AUTOSAR XML (schema 4-0-3)
package /CPLR_Code_pkg/CPLR_Code_swc
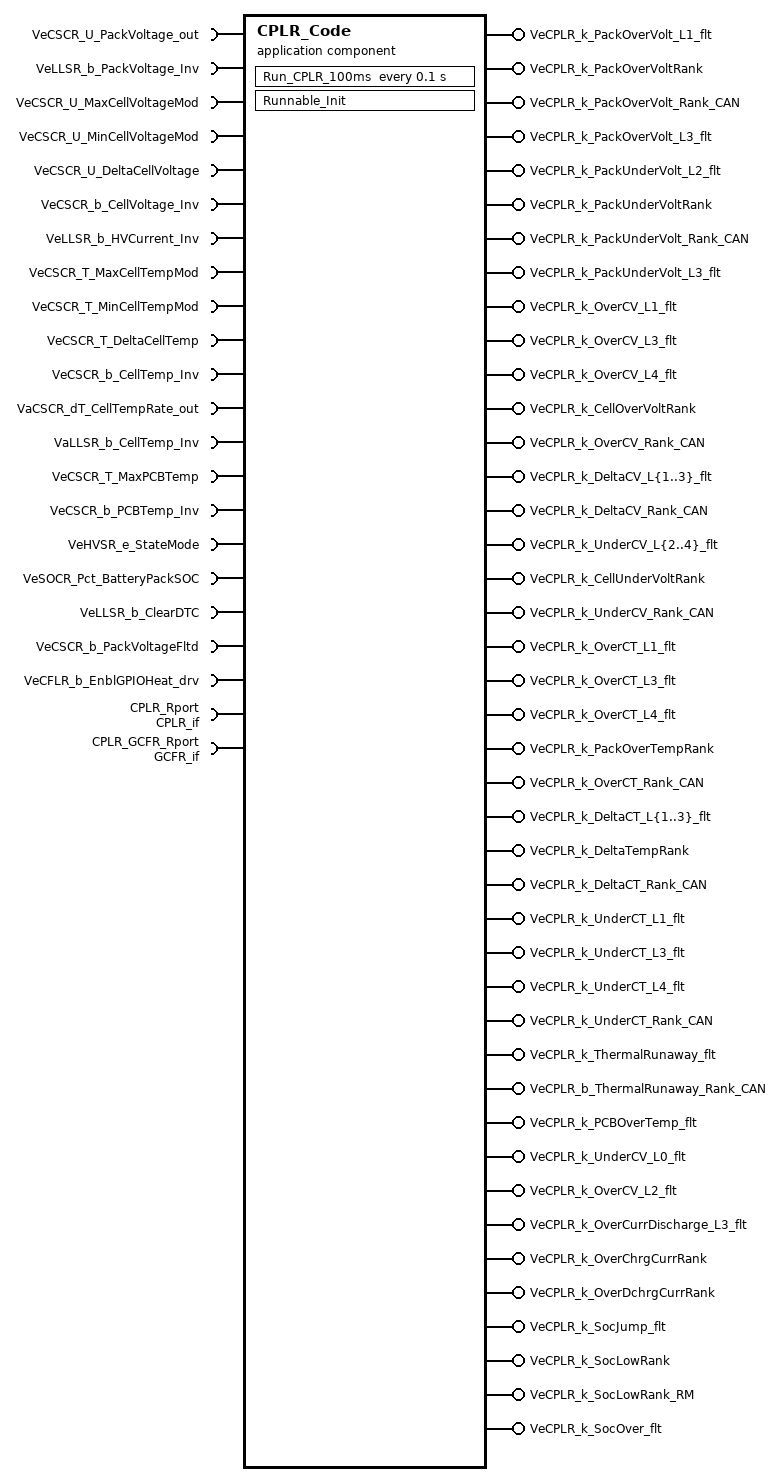
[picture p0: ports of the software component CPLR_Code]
  application sw component type CPLR_Code
    20 x require port:
      VeCSCR_U_PackVoltage_out: nonqueued-receiver-com-spec{data-element=VeCSCR_U_PackVoltage_out, init-value=0}, required-interface=VeCSCR_U_PackVoltage_out
      VeLLSR_b_PackVoltage_Inv: nonqueued-receiver-com-spec{data-element=VeLLSR_b_PackVoltage_Inv, init-value=0}, required-interface=VeLLSR_b_PackVoltage_Inv
      VeCSCR_U_MaxCellVoltageMod: nonqueued-receiver-com-spec{data-element=VeCSCR_U_MaxCellVoltageMod, init-value=0}, required-interface=VeCSCR_U_MaxCellVoltageMod
      VeCSCR_U_MinCellVoltageMod: nonqueued-receiver-com-spec{data-element=VeCSCR_U_MinCellVoltageMod, init-value=0}, required-interface=VeCSCR_U_MinCellVoltageMod
      VeCSCR_U_DeltaCellVoltage: nonqueued-receiver-com-spec{data-element=VeCSCR_U_DeltaCellVoltage, init-value=0}, required-interface=VeCSCR_U_DeltaCellVoltage
      VeCSCR_b_CellVoltage_Inv: nonqueued-receiver-com-spec{data-element=VeCSCR_b_CellVoltage_Inv, init-value=0}, required-interface=VeCSCR_b_CellVoltage_Inv
      VeLLSR_b_HVCurrent_Inv: nonqueued-receiver-com-spec{data-element=VeLLSR_b_HVCurrent_Inv, init-value=0}, required-interface=VeLLSR_b_HVCurrent_Inv
      VeCSCR_T_MaxCellTempMod: nonqueued-receiver-com-spec{data-element=VeCSCR_T_MaxCellTempMod, init-value=0}, required-interface=VeCSCR_T_MaxCellTempMod
      VeCSCR_T_MinCellTempMod: nonqueued-receiver-com-spec{data-element=VeCSCR_T_MinCellTempMod, init-value=0}, required-interface=VeCSCR_T_MinCellTempMod
      VeCSCR_T_DeltaCellTemp: nonqueued-receiver-com-spec{data-element=VeCSCR_T_DeltaCellTemp, init-value=0}, required-interface=VeCSCR_T_DeltaCellTemp
      VeCSCR_b_CellTemp_Inv: nonqueued-receiver-com-spec{data-element=VeCSCR_b_CellTemp_Inv, init-value=0}, required-interface=VeCSCR_b_CellTemp_Inv
      VaCSCR_dT_CellTempRate_out: nonqueued-receiver-com-spec{data-element=VaCSCR_dT_CellTempRate_out, init-value=16 x 0}, required-interface=VaCSCR_dT_CellTempRate_out
      VaLLSR_b_CellTemp_Inv: nonqueued-receiver-com-spec{data-element=VaLLSR_b_CellTemp_Inv, init-value=16 x 0}, required-interface=VaLLSR_b_CellTemp_Inv
      VeCSCR_T_MaxPCBTemp: nonqueued-receiver-com-spec{data-element=VeCSCR_T_MaxPCBTemp, init-value=0}, required-interface=VeCSCR_T_MaxPCBTemp
      VeCSCR_b_PCBTemp_Inv: nonqueued-receiver-com-spec{data-element=VeCSCR_b_PCBTemp_Inv, init-value=0}, required-interface=VeCSCR_b_PCBTemp_Inv
      VeHVSR_e_StateMode: nonqueued-receiver-com-spec{data-element=VeHVSR_e_StateMode, init-value=CeHVSR_e_StateModeReserved}, required-interface=VeHVSR_e_StateMode
      VeSOCR_Pct_BatteryPackSOC: nonqueued-receiver-com-spec{data-element=VeSOCR_Pct_BatteryPackSOC, init-value=0}, required-interface=VeSOCR_Pct_BatteryPackSOC
      VeLLSR_b_ClearDTC: nonqueued-receiver-com-spec{data-element=VeLLSR_b_ClearDTC, init-value=0}, required-interface=VeLLSR_b_ClearDTC
      VeCSCR_b_PackVoltageFltd: nonqueued-receiver-com-spec{data-element=VeCSCR_b_PackVoltageFltd, init-value=0}, required-interface=VeCSCR_b_PackVoltageFltd
      VeCFLR_b_EnblGPIOHeat_drv: nonqueued-receiver-com-spec{data-element=VeCFLR_b_EnblGPIOHeat_drv, init-value=0}, required-interface=VeCFLR_b_EnblGPIOHeat_drv
    48 x provide port:
      VeCPLR_k_PackOverVolt_L1_flt: nonqueued-sender-com-spec{data-element=VeCPLR_k_PackOverVolt_L1_flt, init-value=0}, provided-interface=VeCPLR_k_PackOverVolt_L1_flt
      VeCPLR_k_PackOverVoltRank: nonqueued-sender-com-spec{data-element=VeCPLR_k_PackOverVoltRank, init-value=0}, provided-interface=VeCPLR_k_PackOverVoltRank
      VeCPLR_k_PackOverVolt_Rank_CAN: nonqueued-sender-com-spec{data-element=VeCPLR_k_PackOverVolt_Rank_CAN, init-value=0}, provided-interface=VeCPLR_k_PackOverVolt_Rank_CAN
      VeCPLR_k_PackOverVolt_L3_flt: nonqueued-sender-com-spec{data-element=VeCPLR_k_PackOverVolt_L3_flt, init-value=0}, provided-interface=VeCPLR_k_PackOverVolt_L3_flt
      VeCPLR_k_PackUnderVolt_L2_flt: nonqueued-sender-com-spec{data-element=VeCPLR_k_PackUnderVolt_L2_flt, init-value=0}, provided-interface=VeCPLR_k_PackUnderVolt_L2_flt
      VeCPLR_k_PackUnderVoltRank: nonqueued-sender-com-spec{data-element=VeCPLR_k_PackUnderVoltRank, init-value=0}, provided-interface=VeCPLR_k_PackUnderVoltRank
      VeCPLR_k_PackUnderVolt_Rank_CAN: nonqueued-sender-com-spec{data-element=VeCPLR_k_PackUnderVolt_Rank_CAN, init-value=0}, provided-interface=VeCPLR_k_PackUnderVolt_Rank_CAN
      VeCPLR_k_PackUnderVolt_L3_flt: nonqueued-sender-com-spec{data-element=VeCPLR_k_PackUnderVolt_L3_flt, init-value=0}, provided-interface=VeCPLR_k_PackUnderVolt_L3_flt
      VeCPLR_k_OverCV_L1_flt: nonqueued-sender-com-spec{data-element=VeCPLR_k_OverCV_L1_flt, init-value=0}, provided-interface=VeCPLR_k_OverCV_L1_flt
      VeCPLR_k_OverCV_L3_flt: nonqueued-sender-com-spec{data-element=VeCPLR_k_OverCV_L3_flt, init-value=0}, provided-interface=VeCPLR_k_OverCV_L3_flt
      VeCPLR_k_OverCV_L4_flt: nonqueued-sender-com-spec{data-element=VeCPLR_k_OverCV_L4_flt, init-value=0}, provided-interface=VeCPLR_k_OverCV_L4_flt
      VeCPLR_k_CellOverVoltRank: nonqueued-sender-com-spec{data-element=VeCPLR_k_CellOverVoltRank, init-value=0}, provided-interface=VeCPLR_k_CellOverVoltRank
      VeCPLR_k_OverCV_Rank_CAN: nonqueued-sender-com-spec{data-element=VeCPLR_k_OverCV_Rank_CAN, init-value=0}, provided-interface=VeCPLR_k_OverCV_Rank_CAN
      VeCPLR_k_DeltaCV_L{1..3}_flt: nonqueued-sender-com-spec{data-element=VeCPLR_k_DeltaCV_L{1..3}_flt, init-value=0}, provided-interface=VeCPLR_k_DeltaCV_L{1..3}_flt
      VeCPLR_k_DeltaCV_Rank_CAN: nonqueued-sender-com-spec{data-element=VeCPLR_k_DeltaCV_Rank_CAN, init-value=0}, provided-interface=VeCPLR_k_DeltaCV_Rank_CAN
      VeCPLR_k_UnderCV_L{2..4}_flt: nonqueued-sender-com-spec{data-element=VeCPLR_k_UnderCV_L{2..4}_flt, init-value=0}, provided-interface=VeCPLR_k_UnderCV_L{2..4}_flt
      VeCPLR_k_CellUnderVoltRank: nonqueued-sender-com-spec{data-element=VeCPLR_k_CellUnderVoltRank, init-value=0}, provided-interface=VeCPLR_k_CellUnderVoltRank
      VeCPLR_k_UnderCV_Rank_CAN: nonqueued-sender-com-spec{data-element=VeCPLR_k_UnderCV_Rank_CAN, init-value=0}, provided-interface=VeCPLR_k_UnderCV_Rank_CAN
      VeCPLR_k_OverCT_L1_flt: nonqueued-sender-com-spec{data-element=VeCPLR_k_OverCT_L1_flt, init-value=0}, provided-interface=VeCPLR_k_OverCT_L1_flt
      VeCPLR_k_OverCT_L3_flt: nonqueued-sender-com-spec{data-element=VeCPLR_k_OverCT_L3_flt, init-value=0}, provided-interface=VeCPLR_k_OverCT_L3_flt
      VeCPLR_k_OverCT_L4_flt: nonqueued-sender-com-spec{data-element=VeCPLR_k_OverCT_L4_flt, init-value=0}, provided-interface=VeCPLR_k_OverCT_L4_flt
      VeCPLR_k_PackOverTempRank: nonqueued-sender-com-spec{data-element=VeCPLR_k_PackOverTempRank, init-value=0}, provided-interface=VeCPLR_k_PackOverTempRank
      VeCPLR_k_OverCT_Rank_CAN: nonqueued-sender-com-spec{data-element=VeCPLR_k_OverCT_Rank_CAN, init-value=0}, provided-interface=VeCPLR_k_OverCT_Rank_CAN
      VeCPLR_k_DeltaCT_L{1..3}_flt: nonqueued-sender-com-spec{data-element=VeCPLR_k_DeltaCT_L{1..3}_flt, init-value=0}, provided-interface=VeCPLR_k_DeltaCT_L{1..3}_flt
      VeCPLR_k_DeltaTempRank: nonqueued-sender-com-spec{data-element=VeCPLR_k_DeltaTempRank, init-value=0}, provided-interface=VeCPLR_k_DeltaTempRank
      VeCPLR_k_DeltaCT_Rank_CAN: nonqueued-sender-com-spec{data-element=VeCPLR_k_DeltaCT_Rank_CAN, init-value=0}, provided-interface=VeCPLR_k_DeltaCT_Rank_CAN
      VeCPLR_k_UnderCT_L1_flt: nonqueued-sender-com-spec{data-element=VeCPLR_k_UnderCT_L1_flt, init-value=0}, provided-interface=VeCPLR_k_UnderCT_L1_flt
      VeCPLR_k_UnderCT_L3_flt: nonqueued-sender-com-spec{data-element=VeCPLR_k_UnderCT_L3_flt, init-value=0}, provided-interface=VeCPLR_k_UnderCT_L3_flt
      VeCPLR_k_UnderCT_L4_flt: nonqueued-sender-com-spec{data-element=VeCPLR_k_UnderCT_L4_flt, init-value=0}, provided-interface=VeCPLR_k_UnderCT_L4_flt
      VeCPLR_k_UnderCT_Rank_CAN: nonqueued-sender-com-spec{data-element=VeCPLR_k_UnderCT_Rank_CAN, init-value=0}, provided-interface=VeCPLR_k_UnderCT_Rank_CAN
      VeCPLR_k_ThermalRunaway_flt: nonqueued-sender-com-spec{data-element=VeCPLR_k_ThermalRunaway_flt, init-value=0}, provided-interface=VeCPLR_k_ThermalRunaway_flt
      VeCPLR_b_ThermalRunaway_Rank_CAN: nonqueued-sender-com-spec{data-element=VeCPLR_b_ThermalRunaway_Rank_CAN, init-value=0}, provided-interface=VeCPLR_b_ThermalRunaway_Rank_CAN
      VeCPLR_k_PCBOverTemp_flt: nonqueued-sender-com-spec{data-element=VeCPLR_k_PCBOverTemp_flt, init-value=0}, provided-interface=VeCPLR_k_PCBOverTemp_flt
      VeCPLR_k_UnderCV_L0_flt: nonqueued-sender-com-spec{data-element=VeCPLR_k_UnderCV_L0_flt, init-value=0}, provided-interface=VeCPLR_k_UnderCV_L0_flt
      VeCPLR_k_OverCV_L2_flt: nonqueued-sender-com-spec{data-element=VeCPLR_k_OverCV_L2_flt, init-value=0}, provided-interface=VeCPLR_k_OverCV_L2_flt
      VeCPLR_k_OverCurrDischarge_L3_flt: nonqueued-sender-com-spec{data-element=VeCPLR_k_OverCurrDischarge_L3_flt, init-value=0}, provided-interface=VeCPLR_k_OverCurrDischarge_L3_flt
      VeCPLR_k_OverChrgCurrRank: nonqueued-sender-com-spec{data-element=VeCPLR_k_OverChrgCurrRank, init-value=0}, provided-interface=VeCPLR_k_OverChrgCurrRank
      VeCPLR_k_OverDchrgCurrRank: nonqueued-sender-com-spec{data-element=VeCPLR_k_OverDchrgCurrRank, init-value=0}, provided-interface=VeCPLR_k_OverDchrgCurrRank
      VeCPLR_k_SocJump_flt: nonqueued-sender-com-spec{data-element=VeCPLR_k_SocJump_flt, init-value=0}, provided-interface=VeCPLR_k_SocJump_flt
      VeCPLR_k_SocLowRank: nonqueued-sender-com-spec{data-element=VeCPLR_k_SocLowRank, init-value=0}, provided-interface=VeCPLR_k_SocLowRank
      VeCPLR_k_SocLowRank_RM: nonqueued-sender-com-spec{data-element=VeCPLR_k_SocLowRank_RM, init-value=0}, provided-interface=VeCPLR_k_SocLowRank_RM
      VeCPLR_k_SocOver_flt: nonqueued-sender-com-spec{data-element=VeCPLR_k_SocOver_flt, init-value=0}, provided-interface=VeCPLR_k_SocOver_flt
    require port CPLR_Rport: required-interface=CPLR_if
    require port CPLR_GCFR_Rport: required-interface=GCFR_if
    behavior CPLR_Code: data-type-mapping=[CPLR_CodeDataTypeMappingsSet, WorkingDataTypeMappingsSet], handle-termination-and-restart=NO-SUPPORT
      timing event Event_Run_CPLR_100ms: start-on-event=Run_CPLR_100ms, period=0.1
      runnable Runnable_Init: symbol=CPLR_Code_Init
        data-send-points:
          32 x access:
            OUT_VeCPLR_k_UnderCV_L0_flt_VeCPLR_k_UnderCV_L0_flt: accessed-variable=VeCPLR_k_UnderCV_L0_flt.VeCPLR_k_UnderCV_L0_flt
            OUT_VeCPLR_k_OverCV_L2_flt_VeCPLR_k_OverCV_L2_flt: accessed-variable=VeCPLR_k_OverCV_L2_flt.VeCPLR_k_OverCV_L2_flt
            OUT_VeCPLR_k_OverCurrDischarge_L3_flt_VeCPLR_f7761c5b48d64ec0: accessed-variable=VeCPLR_k_OverCurrDischarge_L3_flt.VeCPLR_k_OverCurrDischarge_L3_flt
            OUT_VeCPLR_k_OverChrgCurrRank_VeCPLR_k_OverChrgCurrRank: accessed-variable=VeCPLR_k_OverChrgCurrRank.VeCPLR_k_OverChrgCurrRank
            OUT_VeCPLR_k_OverDchrgCurrRank_VeCPLR_k_OverDchrgCurrRank: accessed-variable=VeCPLR_k_OverDchrgCurrRank.VeCPLR_k_OverDchrgCurrRank
            OUT_VeCPLR_k_SocJump_flt_VeCPLR_k_SocJump_flt: accessed-variable=VeCPLR_k_SocJump_flt.VeCPLR_k_SocJump_flt
            OUT_VeCPLR_k_SocLowRank_VeCPLR_k_SocLowRank: accessed-variable=VeCPLR_k_SocLowRank.VeCPLR_k_SocLowRank
            OUT_VeCPLR_k_SocLowRank_RM_VeCPLR_k_SocLowRank_RM: accessed-variable=VeCPLR_k_SocLowRank_RM.VeCPLR_k_SocLowRank_RM
            OUT_VeCPLR_k_SocOver_flt_VeCPLR_k_SocOver_flt: accessed-variable=VeCPLR_k_SocOver_flt.VeCPLR_k_SocOver_flt
            OUT_VeCPLR_k_PackOverVolt_L1_flt_VeCPLR_k_PackOverVolt_L1_flt: accessed-variable=VeCPLR_k_PackOverVolt_L1_flt.VeCPLR_k_PackOverVolt_L1_flt
            OUT_VeCPLR_k_PackOverVolt_L3_flt_VeCPLR_k_PackOverVolt_L3_flt: accessed-variable=VeCPLR_k_PackOverVolt_L3_flt.VeCPLR_k_PackOverVolt_L3_flt
            OUT_VeCPLR_k_PackUnderVolt_L2_flt_VeCPLR_k_Pa_e03c45c6c9c0b4ad: accessed-variable=VeCPLR_k_PackUnderVolt_L2_flt.VeCPLR_k_PackUnderVolt_L2_flt
            OUT_VeCPLR_k_PackUnderVolt_L3_flt_VeCPLR_k_Pa_cc559624e727b183: accessed-variable=VeCPLR_k_PackUnderVolt_L3_flt.VeCPLR_k_PackUnderVolt_L3_flt
            OUT_VeCPLR_k_OverCV_L1_flt_VeCPLR_k_OverCV_L1_flt: accessed-variable=VeCPLR_k_OverCV_L1_flt.VeCPLR_k_OverCV_L1_flt
            OUT_VeCPLR_k_OverCV_L3_flt_VeCPLR_k_OverCV_L3_flt: accessed-variable=VeCPLR_k_OverCV_L3_flt.VeCPLR_k_OverCV_L3_flt
            OUT_VeCPLR_k_OverCV_L4_flt_VeCPLR_k_OverCV_L4_flt: accessed-variable=VeCPLR_k_OverCV_L4_flt.VeCPLR_k_OverCV_L4_flt
            OUT_VeCPLR_k_DeltaCV_L{1..3}_flt_VeCPLR_k_DeltaCV_L{1..3}_flt: accessed-variable=VeCPLR_k_DeltaCV_L{1..3}_flt.VeCPLR_k_DeltaCV_L{1..3}_flt
            OUT_VeCPLR_k_UnderCV_L{2..4}_flt_VeCPLR_k_UnderCV_L{2..4}_flt: accessed-variable=VeCPLR_k_UnderCV_L{2..4}_flt.VeCPLR_k_UnderCV_L{2..4}_flt
            OUT_VeCPLR_k_OverCT_L1_flt_VeCPLR_k_OverCT_L1_flt: accessed-variable=VeCPLR_k_OverCT_L1_flt.VeCPLR_k_OverCT_L1_flt
            OUT_VeCPLR_k_OverCT_L3_flt_VeCPLR_k_OverCT_L3_flt: accessed-variable=VeCPLR_k_OverCT_L3_flt.VeCPLR_k_OverCT_L3_flt
            OUT_VeCPLR_k_OverCT_L4_flt_VeCPLR_k_OverCT_L4_flt: accessed-variable=VeCPLR_k_OverCT_L4_flt.VeCPLR_k_OverCT_L4_flt
            OUT_VeCPLR_k_DeltaCT_L{1..3}_flt_VeCPLR_k_DeltaCT_L{1..3}_flt: accessed-variable=VeCPLR_k_DeltaCT_L{1..3}_flt.VeCPLR_k_DeltaCT_L{1..3}_flt
            OUT_VeCPLR_k_UnderCT_L1_flt_VeCPLR_k_UnderCT_L1_flt: accessed-variable=VeCPLR_k_UnderCT_L1_flt.VeCPLR_k_UnderCT_L1_flt
            OUT_VeCPLR_k_UnderCT_L3_flt_VeCPLR_k_UnderCT_L3_flt: accessed-variable=VeCPLR_k_UnderCT_L3_flt.VeCPLR_k_UnderCT_L3_flt
            OUT_VeCPLR_k_UnderCT_L4_flt_VeCPLR_k_UnderCT_L4_flt: accessed-variable=VeCPLR_k_UnderCT_L4_flt.VeCPLR_k_UnderCT_L4_flt
            OUT_VeCPLR_k_ThermalRunaway_flt_VeCPLR_k_ThermalRunaway_flt: accessed-variable=VeCPLR_k_ThermalRunaway_flt.VeCPLR_k_ThermalRunaway_flt
      runnable Run_CPLR_100ms
        data-read-access:
          20 x access:
            IN_VaCSCR_dT_CellTempRate_out_VaCSCR_dT_CellTempRate_out: accessed-variable=VaCSCR_dT_CellTempRate_out.VaCSCR_dT_CellTempRate_out
            IN_VaLLSR_b_CellTemp_Inv_VaLLSR_b_CellTemp_Inv: accessed-variable=VaLLSR_b_CellTemp_Inv.VaLLSR_b_CellTemp_Inv
            IN_VeCFLR_b_EnblGPIOHeat_drv_VeCFLR_b_EnblGPIOHeat_drv: accessed-variable=VeCFLR_b_EnblGPIOHeat_drv.VeCFLR_b_EnblGPIOHeat_drv
            IN_VeCSCR_T_DeltaCellTemp_VeCSCR_T_DeltaCellTemp: accessed-variable=VeCSCR_T_DeltaCellTemp.VeCSCR_T_DeltaCellTemp
            IN_VeCSCR_T_MaxCellTempMod_VeCSCR_T_MaxCellTempMod: accessed-variable=VeCSCR_T_MaxCellTempMod.VeCSCR_T_MaxCellTempMod
            IN_VeCSCR_T_MaxPCBTemp_VeCSCR_T_MaxPCBTemp: accessed-variable=VeCSCR_T_MaxPCBTemp.VeCSCR_T_MaxPCBTemp
            IN_VeCSCR_T_MinCellTempMod_VeCSCR_T_MinCellTempMod: accessed-variable=VeCSCR_T_MinCellTempMod.VeCSCR_T_MinCellTempMod
            IN_VeCSCR_U_DeltaCellVoltage_VeCSCR_U_DeltaCellVoltage: accessed-variable=VeCSCR_U_DeltaCellVoltage.VeCSCR_U_DeltaCellVoltage
            IN_VeCSCR_U_MaxCellVoltageMod_VeCSCR_U_MaxCellVoltageMod: accessed-variable=VeCSCR_U_MaxCellVoltageMod.VeCSCR_U_MaxCellVoltageMod
            IN_VeCSCR_U_MinCellVoltageMod_VeCSCR_U_MinCellVoltageMod: accessed-variable=VeCSCR_U_MinCellVoltageMod.VeCSCR_U_MinCellVoltageMod
            IN_VeCSCR_U_PackVoltage_out_VeCSCR_U_PackVoltage_out: accessed-variable=VeCSCR_U_PackVoltage_out.VeCSCR_U_PackVoltage_out
            IN_VeCSCR_b_CellTemp_Inv_VeCSCR_b_CellTemp_Inv: accessed-variable=VeCSCR_b_CellTemp_Inv.VeCSCR_b_CellTemp_Inv
            IN_VeCSCR_b_CellVoltage_Inv_VeCSCR_b_CellVoltage_Inv: accessed-variable=VeCSCR_b_CellVoltage_Inv.VeCSCR_b_CellVoltage_Inv
            IN_VeCSCR_b_PCBTemp_Inv_VeCSCR_b_PCBTemp_Inv: accessed-variable=VeCSCR_b_PCBTemp_Inv.VeCSCR_b_PCBTemp_Inv
            IN_VeCSCR_b_PackVoltageFltd_VeCSCR_b_PackVoltageFltd: accessed-variable=VeCSCR_b_PackVoltageFltd.VeCSCR_b_PackVoltageFltd
            IN_VeHVSR_e_StateMode_VeHVSR_e_StateMode: accessed-variable=VeHVSR_e_StateMode.VeHVSR_e_StateMode
            IN_VeLLSR_b_ClearDTC_VeLLSR_b_ClearDTC: accessed-variable=VeLLSR_b_ClearDTC.VeLLSR_b_ClearDTC
            IN_VeLLSR_b_HVCurrent_Inv_VeLLSR_b_HVCurrent_Inv: accessed-variable=VeLLSR_b_HVCurrent_Inv.VeLLSR_b_HVCurrent_Inv
            IN_VeLLSR_b_PackVoltage_Inv_VeLLSR_b_PackVoltage_Inv: accessed-variable=VeLLSR_b_PackVoltage_Inv.VeLLSR_b_PackVoltage_Inv
            IN_VeSOCR_Pct_BatteryPackSOC_VeSOCR_Pct_BatteryPackSOC: accessed-variable=VeSOCR_Pct_BatteryPackSOC.VeSOCR_Pct_BatteryPackSOC
        data-send-points:
          48 x access:
            OUT_VeCPLR_k_PackOverVolt_L1_flt_VeCPLR_k_PackOverVolt_L1_flt: accessed-variable=VeCPLR_k_PackOverVolt_L1_flt.VeCPLR_k_PackOverVolt_L1_flt
            OUT_VeCPLR_k_PackOverVoltRank_VeCPLR_k_PackOverVoltRank: accessed-variable=VeCPLR_k_PackOverVoltRank.VeCPLR_k_PackOverVoltRank
            OUT_VeCPLR_k_PackOverVolt_Rank_CAN_VeCPLR_k_P_b2e92d86be282e41: accessed-variable=VeCPLR_k_PackOverVolt_Rank_CAN.VeCPLR_k_PackOverVolt_Rank_CAN
            OUT_VeCPLR_k_PackOverVolt_L3_flt_VeCPLR_k_PackOverVolt_L3_flt: accessed-variable=VeCPLR_k_PackOverVolt_L3_flt.VeCPLR_k_PackOverVolt_L3_flt
            OUT_VeCPLR_k_PackUnderVolt_L2_flt_VeCPLR_k_Pa_e03c45c6c9c0b4ad: accessed-variable=VeCPLR_k_PackUnderVolt_L2_flt.VeCPLR_k_PackUnderVolt_L2_flt
            OUT_VeCPLR_k_PackUnderVoltRank_VeCPLR_k_PackUnderVoltRank: accessed-variable=VeCPLR_k_PackUnderVoltRank.VeCPLR_k_PackUnderVoltRank
            OUT_VeCPLR_k_PackUnderVolt_Rank_CAN_VeCPLR_k_ec56d7bc020496a0: accessed-variable=VeCPLR_k_PackUnderVolt_Rank_CAN.VeCPLR_k_PackUnderVolt_Rank_CAN
            OUT_VeCPLR_k_PackUnderVolt_L3_flt_VeCPLR_k_Pa_cc559624e727b183: accessed-variable=VeCPLR_k_PackUnderVolt_L3_flt.VeCPLR_k_PackUnderVolt_L3_flt
            OUT_VeCPLR_k_OverCV_L1_flt_VeCPLR_k_OverCV_L1_flt: accessed-variable=VeCPLR_k_OverCV_L1_flt.VeCPLR_k_OverCV_L1_flt
            OUT_VeCPLR_k_OverCV_L3_flt_VeCPLR_k_OverCV_L3_flt: accessed-variable=VeCPLR_k_OverCV_L3_flt.VeCPLR_k_OverCV_L3_flt
            OUT_VeCPLR_k_OverCV_L4_flt_VeCPLR_k_OverCV_L4_flt: accessed-variable=VeCPLR_k_OverCV_L4_flt.VeCPLR_k_OverCV_L4_flt
            OUT_VeCPLR_k_CellOverVoltRank_VeCPLR_k_CellOverVoltRank: accessed-variable=VeCPLR_k_CellOverVoltRank.VeCPLR_k_CellOverVoltRank
            OUT_VeCPLR_k_OverCV_Rank_CAN_VeCPLR_k_OverCV_Rank_CAN: accessed-variable=VeCPLR_k_OverCV_Rank_CAN.VeCPLR_k_OverCV_Rank_CAN
            OUT_VeCPLR_k_DeltaCV_L{1..3}_flt_VeCPLR_k_DeltaCV_L{1..3}_flt: accessed-variable=VeCPLR_k_DeltaCV_L{1..3}_flt.VeCPLR_k_DeltaCV_L{1..3}_flt
            OUT_VeCPLR_k_DeltaCV_Rank_CAN_VeCPLR_k_DeltaCV_Rank_CAN: accessed-variable=VeCPLR_k_DeltaCV_Rank_CAN.VeCPLR_k_DeltaCV_Rank_CAN
            OUT_VeCPLR_k_UnderCV_L{2..4}_flt_VeCPLR_k_UnderCV_L{2..4}_flt: accessed-variable=VeCPLR_k_UnderCV_L{2..4}_flt.VeCPLR_k_UnderCV_L{2..4}_flt
            OUT_VeCPLR_k_CellUnderVoltRank_VeCPLR_k_CellUnderVoltRank: accessed-variable=VeCPLR_k_CellUnderVoltRank.VeCPLR_k_CellUnderVoltRank
            OUT_VeCPLR_k_UnderCV_Rank_CAN_VeCPLR_k_UnderCV_Rank_CAN: accessed-variable=VeCPLR_k_UnderCV_Rank_CAN.VeCPLR_k_UnderCV_Rank_CAN
            OUT_VeCPLR_k_OverCT_L1_flt_VeCPLR_k_OverCT_L1_flt: accessed-variable=VeCPLR_k_OverCT_L1_flt.VeCPLR_k_OverCT_L1_flt
            OUT_VeCPLR_k_OverCT_L3_flt_VeCPLR_k_OverCT_L3_flt: accessed-variable=VeCPLR_k_OverCT_L3_flt.VeCPLR_k_OverCT_L3_flt
            OUT_VeCPLR_k_OverCT_L4_flt_VeCPLR_k_OverCT_L4_flt: accessed-variable=VeCPLR_k_OverCT_L4_flt.VeCPLR_k_OverCT_L4_flt
            OUT_VeCPLR_k_PackOverTempRank_VeCPLR_k_PackOverTempRank: accessed-variable=VeCPLR_k_PackOverTempRank.VeCPLR_k_PackOverTempRank
            OUT_VeCPLR_k_OverCT_Rank_CAN_VeCPLR_k_OverCT_Rank_CAN: accessed-variable=VeCPLR_k_OverCT_Rank_CAN.VeCPLR_k_OverCT_Rank_CAN
            OUT_VeCPLR_k_DeltaCT_L{1..3}_flt_VeCPLR_k_DeltaCT_L{1..3}_flt: accessed-variable=VeCPLR_k_DeltaCT_L{1..3}_flt.VeCPLR_k_DeltaCT_L{1..3}_flt
            OUT_VeCPLR_k_DeltaTempRank_VeCPLR_k_DeltaTempRank: accessed-variable=VeCPLR_k_DeltaTempRank.VeCPLR_k_DeltaTempRank
            OUT_VeCPLR_k_DeltaCT_Rank_CAN_VeCPLR_k_DeltaCT_Rank_CAN: accessed-variable=VeCPLR_k_DeltaCT_Rank_CAN.VeCPLR_k_DeltaCT_Rank_CAN
            OUT_VeCPLR_k_UnderCT_L1_flt_VeCPLR_k_UnderCT_L1_flt: accessed-variable=VeCPLR_k_UnderCT_L1_flt.VeCPLR_k_UnderCT_L1_flt
            OUT_VeCPLR_k_UnderCT_L3_flt_VeCPLR_k_UnderCT_L3_flt: accessed-variable=VeCPLR_k_UnderCT_L3_flt.VeCPLR_k_UnderCT_L3_flt
            OUT_VeCPLR_k_UnderCT_L4_flt_VeCPLR_k_UnderCT_L4_flt: accessed-variable=VeCPLR_k_UnderCT_L4_flt.VeCPLR_k_UnderCT_L4_flt
            OUT_VeCPLR_k_UnderCT_Rank_CAN_VeCPLR_k_UnderCT_Rank_CAN: accessed-variable=VeCPLR_k_UnderCT_Rank_CAN.VeCPLR_k_UnderCT_Rank_CAN
            OUT_VeCPLR_k_ThermalRunaway_flt_VeCPLR_k_ThermalRunaway_flt: accessed-variable=VeCPLR_k_ThermalRunaway_flt.VeCPLR_k_ThermalRunaway_flt
            OUT_VeCPLR_b_ThermalRunaway_Rank_CAN_VeCPLR_b_dc09d45ce0f05caf: accessed-variable=VeCPLR_b_ThermalRunaway_Rank_CAN.VeCPLR_b_ThermalRunaway_Rank_CAN
            OUT_VeCPLR_k_PCBOverTemp_flt_VeCPLR_k_PCBOverTemp_flt: accessed-variable=VeCPLR_k_PCBOverTemp_flt.VeCPLR_k_PCBOverTemp_flt
            OUT_VeCPLR_k_UnderCV_L0_flt_VeCPLR_k_UnderCV_L0_flt: accessed-variable=VeCPLR_k_UnderCV_L0_flt.VeCPLR_k_UnderCV_L0_flt
            OUT_VeCPLR_k_OverCV_L2_flt_VeCPLR_k_OverCV_L2_flt: accessed-variable=VeCPLR_k_OverCV_L2_flt.VeCPLR_k_OverCV_L2_flt
            OUT_VeCPLR_k_OverCurrDischarge_L3_flt_VeCPLR_f7761c5b48d64ec0: accessed-variable=VeCPLR_k_OverCurrDischarge_L3_flt.VeCPLR_k_OverCurrDischarge_L3_flt
            OUT_VeCPLR_k_OverChrgCurrRank_VeCPLR_k_OverChrgCurrRank: accessed-variable=VeCPLR_k_OverChrgCurrRank.VeCPLR_k_OverChrgCurrRank
            OUT_VeCPLR_k_OverDchrgCurrRank_VeCPLR_k_OverDchrgCurrRank: accessed-variable=VeCPLR_k_OverDchrgCurrRank.VeCPLR_k_OverDchrgCurrRank
            OUT_VeCPLR_k_SocJump_flt_VeCPLR_k_SocJump_flt: accessed-variable=VeCPLR_k_SocJump_flt.VeCPLR_k_SocJump_flt
            OUT_VeCPLR_k_SocLowRank_VeCPLR_k_SocLowRank: accessed-variable=VeCPLR_k_SocLowRank.VeCPLR_k_SocLowRank
            OUT_VeCPLR_k_SocLowRank_RM_VeCPLR_k_SocLowRank_RM: accessed-variable=VeCPLR_k_SocLowRank_RM.VeCPLR_k_SocLowRank_RM
            OUT_VeCPLR_k_SocOver_flt_VeCPLR_k_SocOver_flt: accessed-variable=VeCPLR_k_SocOver_flt.VeCPLR_k_SocOver_flt
        223 x parameter access:
          CALPRM_CPLR_Rport_KeCPLR_Pct_DeltaCV_L{1..3}_flt_SOC_Set: accessed-parameter=CPLR_Rport.KeCPLR_Pct_DeltaCV_L{1..3}_flt_SOC_Set
          CALPRM_CPLR_Rport_KeCPLR_T_DeltaCT_L1_flt_Reset1: accessed-parameter=CPLR_Rport.KeCPLR_T_DeltaCT_L1_flt_Reset1
          CALPRM_CPLR_Rport_KeCPLR_T_DeltaCT_L1_flt_Reset2: accessed-parameter=CPLR_Rport.KeCPLR_T_DeltaCT_L1_flt_Reset2
          CALPRM_CPLR_Rport_KeCPLR_T_DeltaCT_L1_flt_Set1: accessed-parameter=CPLR_Rport.KeCPLR_T_DeltaCT_L1_flt_Set1
          CALPRM_CPLR_Rport_KeCPLR_T_DeltaCT_L1_flt_Set2: accessed-parameter=CPLR_Rport.KeCPLR_T_DeltaCT_L1_flt_Set2
          CALPRM_CPLR_Rport_KeCPLR_T_DeltaCT_L2_flt_Reset1: accessed-parameter=CPLR_Rport.KeCPLR_T_DeltaCT_L2_flt_Reset1
          CALPRM_CPLR_Rport_KeCPLR_T_DeltaCT_L2_flt_Reset2: accessed-parameter=CPLR_Rport.KeCPLR_T_DeltaCT_L2_flt_Reset2
          CALPRM_CPLR_Rport_KeCPLR_T_DeltaCT_L2_flt_Set1: accessed-parameter=CPLR_Rport.KeCPLR_T_DeltaCT_L2_flt_Set1
          CALPRM_CPLR_Rport_KeCPLR_T_DeltaCT_L2_flt_Set2: accessed-parameter=CPLR_Rport.KeCPLR_T_DeltaCT_L2_flt_Set2
          CALPRM_CPLR_Rport_KeCPLR_T_DeltaCT_L3_flt_Reset1: accessed-parameter=CPLR_Rport.KeCPLR_T_DeltaCT_L3_flt_Reset1
          CALPRM_CPLR_Rport_KeCPLR_T_DeltaCT_L3_flt_Reset2: accessed-parameter=CPLR_Rport.KeCPLR_T_DeltaCT_L3_flt_Reset2
          CALPRM_CPLR_Rport_KeCPLR_T_DeltaCT_L3_flt_Set1: accessed-parameter=CPLR_Rport.KeCPLR_T_DeltaCT_L3_flt_Set1
          CALPRM_CPLR_Rport_KeCPLR_T_DeltaCT_L3_flt_Set2: accessed-parameter=CPLR_Rport.KeCPLR_T_DeltaCT_L3_flt_Set2
          CALPRM_CPLR_Rport_KeCPLR_T_OverCT_L1_flt_Reset: accessed-parameter=CPLR_Rport.KeCPLR_T_OverCT_L1_flt_Reset
          CALPRM_CPLR_Rport_KeCPLR_T_OverCT_L1_flt_Set: accessed-parameter=CPLR_Rport.KeCPLR_T_OverCT_L1_flt_Set
          CALPRM_CPLR_Rport_KeCPLR_T_OverCT_L3_flt_Reset: accessed-parameter=CPLR_Rport.KeCPLR_T_OverCT_L3_flt_Reset
          CALPRM_CPLR_Rport_KeCPLR_T_OverCT_L3_flt_Set: accessed-parameter=CPLR_Rport.KeCPLR_T_OverCT_L3_flt_Set
          CALPRM_CPLR_Rport_KeCPLR_T_OverCT_L4_flt_Set: accessed-parameter=CPLR_Rport.KeCPLR_T_OverCT_L4_flt_Set
          CALPRM_CPLR_Rport_KeCPLR_T_PCBOverTemp_flt_Reset: accessed-parameter=CPLR_Rport.KeCPLR_T_PCBOverTemp_flt_Reset
          CALPRM_CPLR_Rport_KeCPLR_T_PCBOverTemp_flt_Set: accessed-parameter=CPLR_Rport.KeCPLR_T_PCBOverTemp_flt_Set
          CALPRM_CPLR_Rport_KeCPLR_T_PackUnderVolt_L2_flt_Reset1: accessed-parameter=CPLR_Rport.KeCPLR_T_PackUnderVolt_L2_flt_Reset1
          CALPRM_CPLR_Rport_KeCPLR_T_PackUnderVolt_L2_flt_Reset12: accessed-parameter=CPLR_Rport.KeCPLR_T_PackUnderVolt_L2_flt_Reset12
          CALPRM_CPLR_Rport_KeCPLR_T_PackUnderVolt_L2_flt_Reset2: accessed-parameter=CPLR_Rport.KeCPLR_T_PackUnderVolt_L2_flt_Reset2
          CALPRM_CPLR_Rport_KeCPLR_T_PackUnderVolt_L2_flt_Set1: accessed-parameter=CPLR_Rport.KeCPLR_T_PackUnderVolt_L2_flt_Set1
          CALPRM_CPLR_Rport_KeCPLR_T_PackUnderVolt_L2_flt_Set12: accessed-parameter=CPLR_Rport.KeCPLR_T_PackUnderVolt_L2_flt_Set12
          CALPRM_CPLR_Rport_KeCPLR_T_PackUnderVolt_L2_flt_Set2: accessed-parameter=CPLR_Rport.KeCPLR_T_PackUnderVolt_L2_flt_Set2
          CALPRM_CPLR_Rport_KeCPLR_T_PackUnderVolt_L3_flt_Reset1: accessed-parameter=CPLR_Rport.KeCPLR_T_PackUnderVolt_L3_flt_Reset1
          CALPRM_CPLR_Rport_KeCPLR_T_PackUnderVolt_L3_flt_Reset12: accessed-parameter=CPLR_Rport.KeCPLR_T_PackUnderVolt_L3_flt_Reset12
          CALPRM_CPLR_Rport_KeCPLR_T_PackUnderVolt_L3_flt_Reset2: accessed-parameter=CPLR_Rport.KeCPLR_T_PackUnderVolt_L3_flt_Reset2
          CALPRM_CPLR_Rport_KeCPLR_T_PackUnderVolt_L3_flt_Set1: accessed-parameter=CPLR_Rport.KeCPLR_T_PackUnderVolt_L3_flt_Set1
          CALPRM_CPLR_Rport_KeCPLR_T_PackUnderVolt_L3_flt_Set12: accessed-parameter=CPLR_Rport.KeCPLR_T_PackUnderVolt_L3_flt_Set12
          CALPRM_CPLR_Rport_KeCPLR_T_PackUnderVolt_L3_flt_Set2: accessed-parameter=CPLR_Rport.KeCPLR_T_PackUnderVolt_L3_flt_Set2
          CALPRM_CPLR_Rport_KeCPLR_T_ThermalRunaway_flt_Reset: accessed-parameter=CPLR_Rport.KeCPLR_T_ThermalRunaway_flt_Reset
          CALPRM_CPLR_Rport_KeCPLR_T_ThermalRunaway_flt_Set: accessed-parameter=CPLR_Rport.KeCPLR_T_ThermalRunaway_flt_Set
          CALPRM_CPLR_Rport_KeCPLR_T_ThermalRunaway_flt_TDiffReset: accessed-parameter=CPLR_Rport.KeCPLR_T_ThermalRunaway_flt_TDiffReset
          CALPRM_CPLR_Rport_KeCPLR_T_ThermalRunaway_flt_TDiffSet: accessed-parameter=CPLR_Rport.KeCPLR_T_ThermalRunaway_flt_TDiffSet
          CALPRM_CPLR_Rport_KeCPLR_T_UnderCT_L1_flt_Reset: accessed-parameter=CPLR_Rport.KeCPLR_T_UnderCT_L1_flt_Reset
          CALPRM_CPLR_Rport_KeCPLR_T_UnderCT_L1_flt_Set: accessed-parameter=CPLR_Rport.KeCPLR_T_UnderCT_L1_flt_Set
          CALPRM_CPLR_Rport_KeCPLR_T_UnderCT_L3_flt_Reset: accessed-parameter=CPLR_Rport.KeCPLR_T_UnderCT_L3_flt_Reset
          CALPRM_CPLR_Rport_KeCPLR_T_UnderCT_L3_flt_Set: accessed-parameter=CPLR_Rport.KeCPLR_T_UnderCT_L3_flt_Set
          CALPRM_CPLR_Rport_KeCPLR_T_UnderCT_L4_flt_Reset: accessed-parameter=CPLR_Rport.KeCPLR_T_UnderCT_L4_flt_Reset
          CALPRM_CPLR_Rport_KeCPLR_T_UnderCT_L4_flt_Set: accessed-parameter=CPLR_Rport.KeCPLR_T_UnderCT_L4_flt_Set
          CALPRM_CPLR_Rport_KeCPLR_T_UnderCV_L2_flt_Reset1: accessed-parameter=CPLR_Rport.KeCPLR_T_UnderCV_L2_flt_Reset1
          CALPRM_CPLR_Rport_KeCPLR_T_UnderCV_L2_flt_Reset12: accessed-parameter=CPLR_Rport.KeCPLR_T_UnderCV_L2_flt_Reset12
          CALPRM_CPLR_Rport_KeCPLR_T_UnderCV_L2_flt_Reset2: accessed-parameter=CPLR_Rport.KeCPLR_T_UnderCV_L2_flt_Reset2
          CALPRM_CPLR_Rport_KeCPLR_T_UnderCV_L2_flt_Set1: accessed-parameter=CPLR_Rport.KeCPLR_T_UnderCV_L2_flt_Set1
          CALPRM_CPLR_Rport_KeCPLR_T_UnderCV_L2_flt_Set12: accessed-parameter=CPLR_Rport.KeCPLR_T_UnderCV_L2_flt_Set12
          CALPRM_CPLR_Rport_KeCPLR_T_UnderCV_L2_flt_Set2: accessed-parameter=CPLR_Rport.KeCPLR_T_UnderCV_L2_flt_Set2
          CALPRM_CPLR_Rport_KeCPLR_T_UnderCV_L3_flt_Reset1: accessed-parameter=CPLR_Rport.KeCPLR_T_UnderCV_L3_flt_Reset1
          CALPRM_CPLR_Rport_KeCPLR_T_UnderCV_L3_flt_Reset12: accessed-parameter=CPLR_Rport.KeCPLR_T_UnderCV_L3_flt_Reset12
          CALPRM_CPLR_Rport_KeCPLR_T_UnderCV_L3_flt_Reset2: accessed-parameter=CPLR_Rport.KeCPLR_T_UnderCV_L3_flt_Reset2
          CALPRM_CPLR_Rport_KeCPLR_T_UnderCV_L3_flt_Set1: accessed-parameter=CPLR_Rport.KeCPLR_T_UnderCV_L3_flt_Set1
          CALPRM_CPLR_Rport_KeCPLR_T_UnderCV_L3_flt_Set12: accessed-parameter=CPLR_Rport.KeCPLR_T_UnderCV_L3_flt_Set12
          CALPRM_CPLR_Rport_KeCPLR_T_UnderCV_L3_flt_Set2: accessed-parameter=CPLR_Rport.KeCPLR_T_UnderCV_L3_flt_Set2
          CALPRM_CPLR_Rport_KeCPLR_U_DeltaCV_L1_flt_Reset1: accessed-parameter=CPLR_Rport.KeCPLR_U_DeltaCV_L1_flt_Reset1
          CALPRM_CPLR_Rport_KeCPLR_U_DeltaCV_L1_flt_Reset2: accessed-parameter=CPLR_Rport.KeCPLR_U_DeltaCV_L1_flt_Reset2
          CALPRM_CPLR_Rport_KeCPLR_U_DeltaCV_L1_flt_Set1: accessed-parameter=CPLR_Rport.KeCPLR_U_DeltaCV_L1_flt_Set1
          CALPRM_CPLR_Rport_KeCPLR_U_DeltaCV_L1_flt_Set2: accessed-parameter=CPLR_Rport.KeCPLR_U_DeltaCV_L1_flt_Set2
          CALPRM_CPLR_Rport_KeCPLR_U_DeltaCV_L2_flt_Reset1: accessed-parameter=CPLR_Rport.KeCPLR_U_DeltaCV_L2_flt_Reset1
          CALPRM_CPLR_Rport_KeCPLR_U_DeltaCV_L2_flt_Reset2: accessed-parameter=CPLR_Rport.KeCPLR_U_DeltaCV_L2_flt_Reset2
          CALPRM_CPLR_Rport_KeCPLR_U_DeltaCV_L2_flt_Set1: accessed-parameter=CPLR_Rport.KeCPLR_U_DeltaCV_L2_flt_Set1
          CALPRM_CPLR_Rport_KeCPLR_U_DeltaCV_L2_flt_Set2: accessed-parameter=CPLR_Rport.KeCPLR_U_DeltaCV_L2_flt_Set2
          CALPRM_CPLR_Rport_KeCPLR_U_DeltaCV_L3_flt_Reset1: accessed-parameter=CPLR_Rport.KeCPLR_U_DeltaCV_L3_flt_Reset1
          CALPRM_CPLR_Rport_KeCPLR_U_DeltaCV_L3_flt_Reset2: accessed-parameter=CPLR_Rport.KeCPLR_U_DeltaCV_L3_flt_Reset2
          CALPRM_CPLR_Rport_KeCPLR_U_DeltaCV_L3_flt_Set1: accessed-parameter=CPLR_Rport.KeCPLR_U_DeltaCV_L3_flt_Set1
          CALPRM_CPLR_Rport_KeCPLR_U_DeltaCV_L3_flt_Set2: accessed-parameter=CPLR_Rport.KeCPLR_U_DeltaCV_L3_flt_Set2
          CALPRM_CPLR_Rport_KeCPLR_U_OverCV_L1_flt_Reset_OP: accessed-parameter=CPLR_Rport.KeCPLR_U_OverCV_L1_flt_Reset_OP
          CALPRM_CPLR_Rport_KeCPLR_U_OverCV_L1_flt_Set: accessed-parameter=CPLR_Rport.KeCPLR_U_OverCV_L1_flt_Set
          CALPRM_CPLR_Rport_KeCPLR_U_OverCV_L3_flt_Reset_OP: accessed-parameter=CPLR_Rport.KeCPLR_U_OverCV_L3_flt_Reset_OP
          CALPRM_CPLR_Rport_KeCPLR_U_OverCV_L3_flt_Set: accessed-parameter=CPLR_Rport.KeCPLR_U_OverCV_L3_flt_Set
          CALPRM_CPLR_Rport_KeCPLR_U_OverCV_L4_flt_Set: accessed-parameter=CPLR_Rport.KeCPLR_U_OverCV_L4_flt_Set
          CALPRM_CPLR_Rport_KeCPLR_U_OverCV_flt_BatTestSet: accessed-parameter=CPLR_Rport.KeCPLR_U_OverCV_flt_BatTestSet
          CALPRM_CPLR_Rport_KeCPLR_U_PackOverVolt_L1_flt_Reset: accessed-parameter=CPLR_Rport.KeCPLR_U_PackOverVolt_L1_flt_Reset
          CALPRM_CPLR_Rport_KeCPLR_U_PackOverVolt_L1_flt_Set: accessed-parameter=CPLR_Rport.KeCPLR_U_PackOverVolt_L1_flt_Set
          CALPRM_CPLR_Rport_KeCPLR_U_PackOverVolt_L3_flt_Set: accessed-parameter=CPLR_Rport.KeCPLR_U_PackOverVolt_L3_flt_Set
          CALPRM_CPLR_Rport_KeCPLR_U_PackOverVolt_flt_BatTestSet: accessed-parameter=CPLR_Rport.KeCPLR_U_PackOverVolt_flt_BatTestSet
          CALPRM_CPLR_Rport_KeCPLR_U_PackUnderVolt_L2_flt_Reset1: accessed-parameter=CPLR_Rport.KeCPLR_U_PackUnderVolt_L2_flt_Reset1
          CALPRM_CPLR_Rport_KeCPLR_U_PackUnderVolt_L2_flt_Reset2: accessed-parameter=CPLR_Rport.KeCPLR_U_PackUnderVolt_L2_flt_Reset2
          CALPRM_CPLR_Rport_KeCPLR_U_PackUnderVolt_L2_flt_Set1: accessed-parameter=CPLR_Rport.KeCPLR_U_PackUnderVolt_L2_flt_Set1
          CALPRM_CPLR_Rport_KeCPLR_U_PackUnderVolt_L2_flt_Set2: accessed-parameter=CPLR_Rport.KeCPLR_U_PackUnderVolt_L2_flt_Set2
          CALPRM_CPLR_Rport_KeCPLR_U_PackUnderVolt_L3_flt_Reset1: accessed-parameter=CPLR_Rport.KeCPLR_U_PackUnderVolt_L3_flt_Reset1
          CALPRM_CPLR_Rport_KeCPLR_U_PackUnderVolt_L3_flt_Reset2: accessed-parameter=CPLR_Rport.KeCPLR_U_PackUnderVolt_L3_flt_Reset2
          CALPRM_CPLR_Rport_KeCPLR_U_PackUnderVolt_L3_flt_Set1: accessed-parameter=CPLR_Rport.KeCPLR_U_PackUnderVolt_L3_flt_Set1
          CALPRM_CPLR_Rport_KeCPLR_U_PackUnderVolt_L3_flt_Set2: accessed-parameter=CPLR_Rport.KeCPLR_U_PackUnderVolt_L3_flt_Set2
          CALPRM_CPLR_Rport_KeCPLR_U_ThermalRunaway_flt_VMinReset: accessed-parameter=CPLR_Rport.KeCPLR_U_ThermalRunaway_flt_VMinReset
          CALPRM_CPLR_Rport_KeCPLR_U_ThermalRunaway_flt_VMinSet: accessed-parameter=CPLR_Rport.KeCPLR_U_ThermalRunaway_flt_VMinSet
          CALPRM_CPLR_Rport_KeCPLR_U_UnderCV_L2_flt_Reset1: accessed-parameter=CPLR_Rport.KeCPLR_U_UnderCV_L2_flt_Reset1
          CALPRM_CPLR_Rport_KeCPLR_U_UnderCV_L2_flt_Reset2: accessed-parameter=CPLR_Rport.KeCPLR_U_UnderCV_L2_flt_Reset2
          CALPRM_CPLR_Rport_KeCPLR_U_UnderCV_L2_flt_Set1: accessed-parameter=CPLR_Rport.KeCPLR_U_UnderCV_L2_flt_Set1
          CALPRM_CPLR_Rport_KeCPLR_U_UnderCV_L2_flt_Set2: accessed-parameter=CPLR_Rport.KeCPLR_U_UnderCV_L2_flt_Set2
          CALPRM_CPLR_Rport_KeCPLR_U_UnderCV_L3_flt_Reset1: accessed-parameter=CPLR_Rport.KeCPLR_U_UnderCV_L3_flt_Reset1
          CALPRM_CPLR_Rport_KeCPLR_U_UnderCV_L3_flt_Reset2: accessed-parameter=CPLR_Rport.KeCPLR_U_UnderCV_L3_flt_Reset2
          CALPRM_CPLR_Rport_KeCPLR_U_UnderCV_L3_flt_Set1: accessed-parameter=CPLR_Rport.KeCPLR_U_UnderCV_L3_flt_Set1
          CALPRM_CPLR_Rport_KeCPLR_U_UnderCV_L3_flt_Set2: accessed-parameter=CPLR_Rport.KeCPLR_U_UnderCV_L3_flt_Set2
          CALPRM_CPLR_Rport_KeCPLR_U_UnderCV_L4_flt_Set_CH: accessed-parameter=CPLR_Rport.KeCPLR_U_UnderCV_L4_flt_Set_CH
          CALPRM_CPLR_Rport_KeCPLR_U_UnderCV_L4_flt_Set_OP: accessed-parameter=CPLR_Rport.KeCPLR_U_UnderCV_L4_flt_Set_OP
          CALPRM_CPLR_Rport_KeCPLR_b_CellOverVoltRank_En: accessed-parameter=CPLR_Rport.KeCPLR_b_CellOverVoltRank_En
          CALPRM_CPLR_Rport_KeCPLR_b_CellUnderVoltRank_En: accessed-parameter=CPLR_Rport.KeCPLR_b_CellUnderVoltRank_En
          CALPRM_CPLR_Rport_KeCPLR_b_DeltaCT_L{1..3}_flt_En: accessed-parameter=CPLR_Rport.KeCPLR_b_DeltaCT_L{1..3}_flt_En
          CALPRM_CPLR_Rport_KeCPLR_b_DeltaCT_Rank_CAN_En: accessed-parameter=CPLR_Rport.KeCPLR_b_DeltaCT_Rank_CAN_En
          CALPRM_CPLR_Rport_KeCPLR_b_DeltaCV_L{1..3}_flt_En: accessed-parameter=CPLR_Rport.KeCPLR_b_DeltaCV_L{1..3}_flt_En
          CALPRM_CPLR_Rport_KeCPLR_b_DeltaCV_Rank_CAN_En: accessed-parameter=CPLR_Rport.KeCPLR_b_DeltaCV_Rank_CAN_En
          CALPRM_CPLR_Rport_KeCPLR_b_DeltaTempRank_En: accessed-parameter=CPLR_Rport.KeCPLR_b_DeltaTempRank_En
          CALPRM_CPLR_Rport_KeCPLR_b_OverCT_L1_flt_En: accessed-parameter=CPLR_Rport.KeCPLR_b_OverCT_L1_flt_En
          CALPRM_CPLR_Rport_KeCPLR_b_OverCT_L3_flt_En: accessed-parameter=CPLR_Rport.KeCPLR_b_OverCT_L3_flt_En
          CALPRM_CPLR_Rport_KeCPLR_b_OverCT_L4_flt_En: accessed-parameter=CPLR_Rport.KeCPLR_b_OverCT_L4_flt_En
          CALPRM_CPLR_Rport_KeCPLR_b_OverCT_Rank_CAN_En: accessed-parameter=CPLR_Rport.KeCPLR_b_OverCT_Rank_CAN_En
          CALPRM_CPLR_Rport_KeCPLR_b_OverCV_L1_flt_En: accessed-parameter=CPLR_Rport.KeCPLR_b_OverCV_L1_flt_En
          CALPRM_CPLR_Rport_KeCPLR_b_OverCV_L3_flt_En: accessed-parameter=CPLR_Rport.KeCPLR_b_OverCV_L3_flt_En
          CALPRM_CPLR_Rport_KeCPLR_b_OverCV_L4_flt_En: accessed-parameter=CPLR_Rport.KeCPLR_b_OverCV_L4_flt_En
          CALPRM_CPLR_Rport_KeCPLR_b_OverCV_Rank_CAN_En: accessed-parameter=CPLR_Rport.KeCPLR_b_OverCV_Rank_CAN_En
          CALPRM_CPLR_Rport_KeCPLR_b_PCBOverTemp_flt_En: accessed-parameter=CPLR_Rport.KeCPLR_b_PCBOverTemp_flt_En
          CALPRM_CPLR_Rport_KeCPLR_b_PackOverTempRank_En: accessed-parameter=CPLR_Rport.KeCPLR_b_PackOverTempRank_En
          CALPRM_CPLR_Rport_KeCPLR_b_PackOverVoltRank_En: accessed-parameter=CPLR_Rport.KeCPLR_b_PackOverVoltRank_En
          CALPRM_CPLR_Rport_KeCPLR_b_PackOverVolt_L1_flt_En: accessed-parameter=CPLR_Rport.KeCPLR_b_PackOverVolt_L1_flt_En
          CALPRM_CPLR_Rport_KeCPLR_b_PackOverVolt_L3_flt_En: accessed-parameter=CPLR_Rport.KeCPLR_b_PackOverVolt_L3_flt_En
          CALPRM_CPLR_Rport_KeCPLR_b_PackOverVolt_Rank_CAN_En: accessed-parameter=CPLR_Rport.KeCPLR_b_PackOverVolt_Rank_CAN_En
          CALPRM_CPLR_Rport_KeCPLR_b_PackUnderVoltRank_En: accessed-parameter=CPLR_Rport.KeCPLR_b_PackUnderVoltRank_En
          CALPRM_CPLR_Rport_KeCPLR_b_PackUnderVolt_L2_flt_En: accessed-parameter=CPLR_Rport.KeCPLR_b_PackUnderVolt_L2_flt_En
          CALPRM_CPLR_Rport_KeCPLR_b_PackUnderVolt_L3_flt_En: accessed-parameter=CPLR_Rport.KeCPLR_b_PackUnderVolt_L3_flt_En
          CALPRM_CPLR_Rport_KeCPLR_b_PackUnderVolt_Rank_CAN_En: accessed-parameter=CPLR_Rport.KeCPLR_b_PackUnderVolt_Rank_CAN_En
          CALPRM_CPLR_Rport_KeCPLR_b_ThermalRunaway_Rank_CAN_En: accessed-parameter=CPLR_Rport.KeCPLR_b_ThermalRunaway_Rank_CAN_En
          CALPRM_CPLR_Rport_KeCPLR_b_ThermalRunaway_Rank_CAN_Val: accessed-parameter=CPLR_Rport.KeCPLR_b_ThermalRunaway_Rank_CAN_Val
          CALPRM_CPLR_Rport_KeCPLR_b_ThermalRunaway_flt_En: accessed-parameter=CPLR_Rport.KeCPLR_b_ThermalRunaway_flt_En
          CALPRM_CPLR_Rport_KeCPLR_b_UnderCT_L1_flt_En: accessed-parameter=CPLR_Rport.KeCPLR_b_UnderCT_L1_flt_En
          CALPRM_CPLR_Rport_KeCPLR_b_UnderCT_L3_flt_En: accessed-parameter=CPLR_Rport.KeCPLR_b_UnderCT_L3_flt_En
          CALPRM_CPLR_Rport_KeCPLR_b_UnderCT_L4_flt_En: accessed-parameter=CPLR_Rport.KeCPLR_b_UnderCT_L4_flt_En
          CALPRM_CPLR_Rport_KeCPLR_b_UnderCT_Rank_CAN_En: accessed-parameter=CPLR_Rport.KeCPLR_b_UnderCT_Rank_CAN_En
          CALPRM_CPLR_Rport_KeCPLR_b_UnderCV_L{2..4}_flt_En: accessed-parameter=CPLR_Rport.KeCPLR_b_UnderCV_L{2..4}_flt_En
          CALPRM_CPLR_Rport_KeCPLR_b_UnderCV_Rank_CAN_En: accessed-parameter=CPLR_Rport.KeCPLR_b_UnderCV_Rank_CAN_En
          CALPRM_CPLR_Rport_KeCPLR_dT_ThermalRunaway_flt_Set: accessed-parameter=CPLR_Rport.KeCPLR_dT_ThermalRunaway_flt_Set
          CALPRM_CPLR_Rport_KeCPLR_k_CellOverVoltRank_Val: accessed-parameter=CPLR_Rport.KeCPLR_k_CellOverVoltRank_Val
          CALPRM_CPLR_Rport_KeCPLR_k_CellUnderVoltRank_Val: accessed-parameter=CPLR_Rport.KeCPLR_k_CellUnderVoltRank_Val
          CALPRM_CPLR_Rport_KeCPLR_k_DeltaCT_L{1..3}_flt_Val: accessed-parameter=CPLR_Rport.KeCPLR_k_DeltaCT_L{1..3}_flt_Val
          CALPRM_CPLR_Rport_KeCPLR_k_DeltaCT_Rank_CAN_Val: accessed-parameter=CPLR_Rport.KeCPLR_k_DeltaCT_Rank_CAN_Val
          CALPRM_CPLR_Rport_KeCPLR_k_DeltaCV_L{1..3}_flt_Val: accessed-parameter=CPLR_Rport.KeCPLR_k_DeltaCV_L{1..3}_flt_Val
          CALPRM_CPLR_Rport_KeCPLR_k_DeltaCV_Rank_CAN_Val: accessed-parameter=CPLR_Rport.KeCPLR_k_DeltaCV_Rank_CAN_Val
          CALPRM_CPLR_Rport_KeCPLR_k_DeltaTempRank_Val: accessed-parameter=CPLR_Rport.KeCPLR_k_DeltaTempRank_Val
          CALPRM_CPLR_Rport_KeCPLR_k_OverCT_L1_flt_Val: accessed-parameter=CPLR_Rport.KeCPLR_k_OverCT_L1_flt_Val
          CALPRM_CPLR_Rport_KeCPLR_k_OverCT_L3_flt_Val: accessed-parameter=CPLR_Rport.KeCPLR_k_OverCT_L3_flt_Val
          CALPRM_CPLR_Rport_KeCPLR_k_OverCT_L4_flt_Val: accessed-parameter=CPLR_Rport.KeCPLR_k_OverCT_L4_flt_Val
          CALPRM_CPLR_Rport_KeCPLR_k_OverCT_Rank_CAN_Val: accessed-parameter=CPLR_Rport.KeCPLR_k_OverCT_Rank_CAN_Val
          CALPRM_CPLR_Rport_KeCPLR_k_OverCV_L1_flt_Val: accessed-parameter=CPLR_Rport.KeCPLR_k_OverCV_L1_flt_Val
          CALPRM_CPLR_Rport_KeCPLR_k_OverCV_L3_flt_Val: accessed-parameter=CPLR_Rport.KeCPLR_k_OverCV_L3_flt_Val
          CALPRM_CPLR_Rport_KeCPLR_k_OverCV_L4_flt_Val: accessed-parameter=CPLR_Rport.KeCPLR_k_OverCV_L4_flt_Val
          CALPRM_CPLR_Rport_KeCPLR_k_OverCV_Rank_CAN_Val: accessed-parameter=CPLR_Rport.KeCPLR_k_OverCV_Rank_CAN_Val
          CALPRM_CPLR_Rport_KeCPLR_k_PCBOverTemp_flt_Val: accessed-parameter=CPLR_Rport.KeCPLR_k_PCBOverTemp_flt_Val
          CALPRM_CPLR_Rport_KeCPLR_k_PackOverTempRank_Val: accessed-parameter=CPLR_Rport.KeCPLR_k_PackOverTempRank_Val
          CALPRM_CPLR_Rport_KeCPLR_k_PackOverVoltRank_Val: accessed-parameter=CPLR_Rport.KeCPLR_k_PackOverVoltRank_Val
          CALPRM_CPLR_Rport_KeCPLR_k_PackOverVolt_L1_flt_Val: accessed-parameter=CPLR_Rport.KeCPLR_k_PackOverVolt_L1_flt_Val
          CALPRM_CPLR_Rport_KeCPLR_k_PackOverVolt_L3_flt_Val: accessed-parameter=CPLR_Rport.KeCPLR_k_PackOverVolt_L3_flt_Val
          CALPRM_CPLR_Rport_KeCPLR_k_PackOverVolt_Rank_CAN_Val: accessed-parameter=CPLR_Rport.KeCPLR_k_PackOverVolt_Rank_CAN_Val
          CALPRM_CPLR_Rport_KeCPLR_k_PackUnderVoltRank_Val: accessed-parameter=CPLR_Rport.KeCPLR_k_PackUnderVoltRank_Val
          CALPRM_CPLR_Rport_KeCPLR_k_PackUnderVolt_L2_flt_Val: accessed-parameter=CPLR_Rport.KeCPLR_k_PackUnderVolt_L2_flt_Val
          CALPRM_CPLR_Rport_KeCPLR_k_PackUnderVolt_L3_flt_Val: accessed-parameter=CPLR_Rport.KeCPLR_k_PackUnderVolt_L3_flt_Val
          CALPRM_CPLR_Rport_KeCPLR_k_PackUnderVolt_Rank_CAN_Val: accessed-parameter=CPLR_Rport.KeCPLR_k_PackUnderVolt_Rank_CAN_Val
          CALPRM_CPLR_Rport_KeCPLR_k_ThermalRunaway_flt_Val: accessed-parameter=CPLR_Rport.KeCPLR_k_ThermalRunaway_flt_Val
          CALPRM_CPLR_Rport_KeCPLR_k_UnderCT_L1_flt_Val: accessed-parameter=CPLR_Rport.KeCPLR_k_UnderCT_L1_flt_Val
          CALPRM_CPLR_Rport_KeCPLR_k_UnderCT_L3_flt_Val: accessed-parameter=CPLR_Rport.KeCPLR_k_UnderCT_L3_flt_Val
          CALPRM_CPLR_Rport_KeCPLR_k_UnderCT_L4_flt_Val: accessed-parameter=CPLR_Rport.KeCPLR_k_UnderCT_L4_flt_Val
          CALPRM_CPLR_Rport_KeCPLR_k_UnderCT_Rank_CAN_Val: accessed-parameter=CPLR_Rport.KeCPLR_k_UnderCT_Rank_CAN_Val
          CALPRM_CPLR_Rport_KeCPLR_k_UnderCV_L{2..4}_flt_Val: accessed-parameter=CPLR_Rport.KeCPLR_k_UnderCV_L{2..4}_flt_Val
          CALPRM_CPLR_Rport_KeCPLR_k_UnderCV_Rank_CAN_Val: accessed-parameter=CPLR_Rport.KeCPLR_k_UnderCV_Rank_CAN_Val
          CALPRM_CPLR_Rport_KeCPLR_t_DeltaCT_L1_flt_Reset: accessed-parameter=CPLR_Rport.KeCPLR_t_DeltaCT_L1_flt_Reset
          CALPRM_CPLR_Rport_KeCPLR_t_DeltaCT_L1_flt_Set: accessed-parameter=CPLR_Rport.KeCPLR_t_DeltaCT_L1_flt_Set
          CALPRM_CPLR_Rport_KeCPLR_t_DeltaCT_L2_flt_Reset: accessed-parameter=CPLR_Rport.KeCPLR_t_DeltaCT_L2_flt_Reset
          CALPRM_CPLR_Rport_KeCPLR_t_DeltaCT_L2_flt_Set: accessed-parameter=CPLR_Rport.KeCPLR_t_DeltaCT_L2_flt_Set
          CALPRM_CPLR_Rport_KeCPLR_t_DeltaCT_L3_flt_Reset: accessed-parameter=CPLR_Rport.KeCPLR_t_DeltaCT_L3_flt_Reset
          CALPRM_CPLR_Rport_KeCPLR_t_DeltaCT_L3_flt_Set: accessed-parameter=CPLR_Rport.KeCPLR_t_DeltaCT_L3_flt_Set
          CALPRM_CPLR_Rport_KeCPLR_t_DeltaCV_L1_flt: accessed-parameter=CPLR_Rport.KeCPLR_t_DeltaCV_L1_flt
          CALPRM_CPLR_Rport_KeCPLR_t_DeltaCV_L1_flt_Reset: accessed-parameter=CPLR_Rport.KeCPLR_t_DeltaCV_L1_flt_Reset
          CALPRM_CPLR_Rport_KeCPLR_t_DeltaCV_L2_flt: accessed-parameter=CPLR_Rport.KeCPLR_t_DeltaCV_L2_flt
          CALPRM_CPLR_Rport_KeCPLR_t_DeltaCV_L2_flt_Reset: accessed-parameter=CPLR_Rport.KeCPLR_t_DeltaCV_L2_flt_Reset
          CALPRM_CPLR_Rport_KeCPLR_t_DeltaCV_L3_flt: accessed-parameter=CPLR_Rport.KeCPLR_t_DeltaCV_L3_flt
          CALPRM_CPLR_Rport_KeCPLR_t_DeltaCV_L3_flt_Reset: accessed-parameter=CPLR_Rport.KeCPLR_t_DeltaCV_L3_flt_Reset
          CALPRM_CPLR_Rport_KeCPLR_t_OverCT_L1_flt_Reset: accessed-parameter=CPLR_Rport.KeCPLR_t_OverCT_L1_flt_Reset
          CALPRM_CPLR_Rport_KeCPLR_t_OverCT_L1_flt_Set: accessed-parameter=CPLR_Rport.KeCPLR_t_OverCT_L1_flt_Set
          CALPRM_CPLR_Rport_KeCPLR_t_OverCT_L3_flt_Reset: accessed-parameter=CPLR_Rport.KeCPLR_t_OverCT_L3_flt_Reset
          CALPRM_CPLR_Rport_KeCPLR_t_OverCT_L3_flt_Set: accessed-parameter=CPLR_Rport.KeCPLR_t_OverCT_L3_flt_Set
          CALPRM_CPLR_Rport_KeCPLR_t_OverCT_L4_flt_Set: accessed-parameter=CPLR_Rport.KeCPLR_t_OverCT_L4_flt_Set
          CALPRM_CPLR_Rport_KeCPLR_t_OverCV_L1_flt_Reset_OP: accessed-parameter=CPLR_Rport.KeCPLR_t_OverCV_L1_flt_Reset_OP
          CALPRM_CPLR_Rport_KeCPLR_t_OverCV_L1_flt_Set: accessed-parameter=CPLR_Rport.KeCPLR_t_OverCV_L1_flt_Set
          CALPRM_CPLR_Rport_KeCPLR_t_OverCV_L3_flt_Reset_OP: accessed-parameter=CPLR_Rport.KeCPLR_t_OverCV_L3_flt_Reset_OP
          CALPRM_CPLR_Rport_KeCPLR_t_OverCV_L3_flt_Set: accessed-parameter=CPLR_Rport.KeCPLR_t_OverCV_L3_flt_Set
          CALPRM_CPLR_Rport_KeCPLR_t_OverCV_L4_flt_Set: accessed-parameter=CPLR_Rport.KeCPLR_t_OverCV_L4_flt_Set
          CALPRM_CPLR_Rport_KeCPLR_t_PCBOverTemp_flt_Set: accessed-parameter=CPLR_Rport.KeCPLR_t_PCBOverTemp_flt_Set
          CALPRM_CPLR_Rport_KeCPLR_t_PackOverVolt_L1_flt_Reset: accessed-parameter=CPLR_Rport.KeCPLR_t_PackOverVolt_L1_flt_Reset
          CALPRM_CPLR_Rport_KeCPLR_t_PackOverVolt_L1_flt_Set: accessed-parameter=CPLR_Rport.KeCPLR_t_PackOverVolt_L1_flt_Set
          CALPRM_CPLR_Rport_KeCPLR_t_PackOverVolt_L3_flt_Set: accessed-parameter=CPLR_Rport.KeCPLR_t_PackOverVolt_L3_flt_Set
          CALPRM_CPLR_Rport_KeCPLR_t_PackUnderVolt_L2_flt_Reset: accessed-parameter=CPLR_Rport.KeCPLR_t_PackUnderVolt_L2_flt_Reset
          CALPRM_CPLR_Rport_KeCPLR_t_PackUnderVolt_L2_flt_Set: accessed-parameter=CPLR_Rport.KeCPLR_t_PackUnderVolt_L2_flt_Set
          CALPRM_CPLR_Rport_KeCPLR_t_PackUnderVolt_L3_flt_Reset: accessed-parameter=CPLR_Rport.KeCPLR_t_PackUnderVolt_L3_flt_Reset
          CALPRM_CPLR_Rport_KeCPLR_t_PackUnderVolt_L3_flt_Set: accessed-parameter=CPLR_Rport.KeCPLR_t_PackUnderVolt_L3_flt_Set
          CALPRM_CPLR_Rport_KeCPLR_t_ThermalRunaway_flt_Set: accessed-parameter=CPLR_Rport.KeCPLR_t_ThermalRunaway_flt_Set
          CALPRM_CPLR_Rport_KeCPLR_t_ThermalRunaway_flt_TdiffSet: accessed-parameter=CPLR_Rport.KeCPLR_t_ThermalRunaway_flt_TdiffSet
          CALPRM_CPLR_Rport_KeCPLR_t_ThermalRunaway_flt_TmaxSet: accessed-parameter=CPLR_Rport.KeCPLR_t_ThermalRunaway_flt_TmaxSet
          CALPRM_CPLR_Rport_KeCPLR_t_ThermalRunaway_flt_VminSet: accessed-parameter=CPLR_Rport.KeCPLR_t_ThermalRunaway_flt_VminSet
          CALPRM_CPLR_Rport_KeCPLR_t_UnderCT_L1_flt_Reset: accessed-parameter=CPLR_Rport.KeCPLR_t_UnderCT_L1_flt_Reset
          CALPRM_CPLR_Rport_KeCPLR_t_UnderCT_L1_flt_Set: accessed-parameter=CPLR_Rport.KeCPLR_t_UnderCT_L1_flt_Set
          CALPRM_CPLR_Rport_KeCPLR_t_UnderCT_L3_flt_Reset: accessed-parameter=CPLR_Rport.KeCPLR_t_UnderCT_L3_flt_Reset
          CALPRM_CPLR_Rport_KeCPLR_t_UnderCT_L3_flt_Set: accessed-parameter=CPLR_Rport.KeCPLR_t_UnderCT_L3_flt_Set
          CALPRM_CPLR_Rport_KeCPLR_t_UnderCT_L4_flt_Reset: accessed-parameter=CPLR_Rport.KeCPLR_t_UnderCT_L4_flt_Reset
          CALPRM_CPLR_Rport_KeCPLR_t_UnderCT_L4_flt_Set: accessed-parameter=CPLR_Rport.KeCPLR_t_UnderCT_L4_flt_Set
          CALPRM_CPLR_Rport_KeCPLR_t_UnderCV_L2_flt_Reset: accessed-parameter=CPLR_Rport.KeCPLR_t_UnderCV_L2_flt_Reset
          CALPRM_CPLR_Rport_KeCPLR_t_UnderCV_L2_flt_Set: accessed-parameter=CPLR_Rport.KeCPLR_t_UnderCV_L2_flt_Set
          CALPRM_CPLR_Rport_KeCPLR_t_UnderCV_L3_flt_Reset: accessed-parameter=CPLR_Rport.KeCPLR_t_UnderCV_L3_flt_Reset
          CALPRM_CPLR_Rport_KeCPLR_t_UnderCV_L3_flt_Set: accessed-parameter=CPLR_Rport.KeCPLR_t_UnderCV_L3_flt_Set
          CALPRM_CPLR_Rport_KeCPLR_t_UnderCV_L4_flt_Set: accessed-parameter=CPLR_Rport.KeCPLR_t_UnderCV_L4_flt_Set
          CALPRM_CPLR_GCFR_Rport_KeGCFR_Cnt_NumberofTempReadings: accessed-parameter=CPLR_GCFR_Rport.KeGCFR_Cnt_NumberofTempReadings
package /CalibrationComponents
  parameter sw component type CPLR: data-type-mapping=[CPLR_CodeDataTypeMappingsSet, WorkingDataTypeMappingsSet]
    provide port CPLR_Pport: provided-interface=CPLR_if
      provided-com-specs:
        init-value=15, parameter=KeCPLR_Pct_DeltaCV_L{1..3}_flt_SOC_Set
        init-value=5, parameter=KeCPLR_T_DeltaCT_L1_flt_Reset1
        init-value=10, parameter=KeCPLR_T_DeltaCT_L1_flt_Reset2
        init-value=8, parameter=KeCPLR_T_DeltaCT_L1_flt_Set1
        init-value=12, parameter=KeCPLR_T_DeltaCT_L1_flt_Set2
        init-value=8, parameter=KeCPLR_T_DeltaCT_L2_flt_Reset1
        init-value=12, parameter=KeCPLR_T_DeltaCT_L2_flt_Reset2
        init-value=12, parameter=KeCPLR_T_DeltaCT_L2_flt_Set1
        init-value=14, parameter=KeCPLR_T_DeltaCT_L2_flt_Set2
        init-value=12, parameter=KeCPLR_T_DeltaCT_L3_flt_Reset1
        init-value=14, parameter=KeCPLR_T_DeltaCT_L3_flt_Reset2
        init-value=15, parameter=KeCPLR_T_DeltaCT_L3_flt_Set1
        init-value=15, parameter=KeCPLR_T_DeltaCT_L3_flt_Set2
        init-value=-10, parameter=KeCPLR_T_DeltaCT_flt_Set_TM
        init-value=43, parameter=KeCPLR_T_OverCT_L1_flt_Reset
        init-value=45, parameter=KeCPLR_T_OverCT_L1_flt_Set
        init-value=48, parameter=KeCPLR_T_OverCT_L3_flt_Reset
        init-value=50, parameter=KeCPLR_T_OverCT_L3_flt_Set
        init-value=55, parameter=KeCPLR_T_OverCT_L4_flt_Set
        init-value=65, parameter=KeCPLR_T_PCBOverTemp_flt_Reset
        init-value=85, parameter=KeCPLR_T_PCBOverTemp_flt_Set
        init-value=-30, parameter=KeCPLR_T_PackUnderVolt_L2_flt_Reset1
        init-value=0, parameter=KeCPLR_T_PackUnderVolt_L2_flt_Reset12
        init-value=55, parameter=KeCPLR_T_PackUnderVolt_L2_flt_Reset2
        init-value=-30, parameter=KeCPLR_T_PackUnderVolt_L2_flt_Set1
        init-value=0, parameter=KeCPLR_T_PackUnderVolt_L2_flt_Set12
        init-value=55, parameter=KeCPLR_T_PackUnderVolt_L2_flt_Set2
        init-value=-30, parameter=KeCPLR_T_PackUnderVolt_L3_flt_Reset1
        init-value=0, parameter=KeCPLR_T_PackUnderVolt_L3_flt_Reset12
        init-value=55, parameter=KeCPLR_T_PackUnderVolt_L3_flt_Reset2
        init-value=-30, parameter=KeCPLR_T_PackUnderVolt_L3_flt_Set1
        init-value=0, parameter=KeCPLR_T_PackUnderVolt_L3_flt_Set12
        init-value=55, parameter=KeCPLR_T_PackUnderVolt_L3_flt_Set2
        init-value=55, parameter=KeCPLR_T_ThermalRunaway_flt_Reset
        init-value=80, parameter=KeCPLR_T_ThermalRunaway_flt_Set
        init-value=15, parameter=KeCPLR_T_ThermalRunaway_flt_TDiffReset
        init-value=30, parameter=KeCPLR_T_ThermalRunaway_flt_TDiffSet
        init-value=-20, parameter=KeCPLR_T_UnderCT_L1_flt_Reset
        init-value=-20, parameter=KeCPLR_T_UnderCT_L1_flt_Set
        init-value=-30, parameter=KeCPLR_T_UnderCT_L3_flt_Reset
        init-value=-30, parameter=KeCPLR_T_UnderCT_L3_flt_Set
        init-value=-35, parameter=KeCPLR_T_UnderCT_L4_flt_Reset
        init-value=-35, parameter=KeCPLR_T_UnderCT_L4_flt_Set
        init-value=-30, parameter=KeCPLR_T_UnderCV_L2_flt_Reset1
        init-value=0, parameter=KeCPLR_T_UnderCV_L2_flt_Reset12
        init-value=55, parameter=KeCPLR_T_UnderCV_L2_flt_Reset2
        init-value=-30, parameter=KeCPLR_T_UnderCV_L2_flt_Set1
        init-value=0, parameter=KeCPLR_T_UnderCV_L2_flt_Set12
        init-value=55, parameter=KeCPLR_T_UnderCV_L2_flt_Set2
        init-value=-30, parameter=KeCPLR_T_UnderCV_L3_flt_Reset1
        init-value=0, parameter=KeCPLR_T_UnderCV_L3_flt_Reset12
        init-value=55, parameter=KeCPLR_T_UnderCV_L3_flt_Reset2
        init-value=-30, parameter=KeCPLR_T_UnderCV_L3_flt_Set1
        init-value=0, parameter=KeCPLR_T_UnderCV_L3_flt_Set12
        init-value=55, parameter=KeCPLR_T_UnderCV_L3_flt_Set2
        init-value=0.20000000298023224, parameter=KeCPLR_U_DeltaCV_L1_flt_Reset1
        init-value=0.10000000149011612, parameter=KeCPLR_U_DeltaCV_L1_flt_Reset2
        init-value=0.25, parameter=KeCPLR_U_DeltaCV_L1_flt_Set1
        init-value=0.15000000596046448, parameter=KeCPLR_U_DeltaCV_L1_flt_Set2
        init-value=0.27000001072883606, parameter=KeCPLR_U_DeltaCV_L2_flt_Reset1
        init-value=0.17000000178813934, parameter=KeCPLR_U_DeltaCV_L2_flt_Reset2
        init-value=0.30000001192092896, parameter=KeCPLR_U_DeltaCV_L2_flt_Set1
        init-value=0.20000000298023224, parameter=KeCPLR_U_DeltaCV_L2_flt_Set2
        init-value=0.3499999940395355, parameter=KeCPLR_U_DeltaCV_L3_flt_Reset1
        init-value=0.25, parameter=KeCPLR_U_DeltaCV_L3_flt_Reset2
        init-value=0.4000000059604645, parameter=KeCPLR_U_DeltaCV_L3_flt_Set1
        init-value=0.30000001192092896, parameter=KeCPLR_U_DeltaCV_L3_flt_Set2
        init-value=4.159999847412109, parameter=KeCPLR_U_OverCV_L1_flt_Reset_OP
        init-value=4.179999828338623, parameter=KeCPLR_U_OverCV_L1_flt_Set
        init-value=4.199999809265137, parameter=KeCPLR_U_OverCV_L3_flt_Reset_OP
        init-value=4.21999979019165, parameter=KeCPLR_U_OverCV_L3_flt_Set
        init-value=4.25, parameter=KeCPLR_U_OverCV_L4_flt_Set
        init-value=4.28000020980835, parameter=KeCPLR_U_OverCV_flt_BatTestSet
        init-value=399.3599853515625, parameter=KeCPLR_U_PackOverVolt_L1_flt_Reset
        init-value=401.0880126953125, parameter=KeCPLR_U_PackOverVolt_L1_flt_Set
        init-value=403.1999816894531, parameter=KeCPLR_U_PackOverVolt_L3_flt_Set
        init-value=408.96002197265625, parameter=KeCPLR_U_PackOverVolt_flt_BatTestSet
        init-value=259.20001220703125, parameter=KeCPLR_U_PackUnderVolt_L2_flt_Reset1
        init-value=288, parameter=KeCPLR_U_PackUnderVolt_L2_flt_Reset2
        init-value=249.59999084472656, parameter=KeCPLR_U_PackUnderVolt_L2_flt_Set1
        init-value=268.79998779296875, parameter=KeCPLR_U_PackUnderVolt_L2_flt_Set2
        init-value=240, parameter=KeCPLR_U_PackUnderVolt_L3_flt_Reset1
        init-value=259.20001220703125, parameter=KeCPLR_U_PackUnderVolt_L3_flt_Reset2
        init-value=230.40000915527344, parameter=KeCPLR_U_PackUnderVolt_L3_flt_Set1
        init-value=249.59999084472656, parameter=KeCPLR_U_PackUnderVolt_L3_flt_Set2
        init-value=2.5, parameter=KeCPLR_U_ThermalRunaway_flt_VMinReset
        init-value=2.299999952316284, parameter=KeCPLR_U_ThermalRunaway_flt_VMinSet
        init-value=2.799999952316284, parameter=KeCPLR_U_UnderCV_L2_flt_Reset1
        init-value=3, parameter=KeCPLR_U_UnderCV_L2_flt_Reset2
        init-value=2.5999999046325684, parameter=KeCPLR_U_UnderCV_L2_flt_Set1
        init-value=2.799999952316284, parameter=KeCPLR_U_UnderCV_L2_flt_Set2
        init-value=2.5, parameter=KeCPLR_U_UnderCV_L3_flt_Reset1
        init-value=2.700000047683716, parameter=KeCPLR_U_UnderCV_L3_flt_Reset2
        init-value=2.4000000953674316, parameter=KeCPLR_U_UnderCV_L3_flt_Set1
        init-value=2.5999999046325684, parameter=KeCPLR_U_UnderCV_L3_flt_Set2
        init-value=2, parameter=KeCPLR_U_UnderCV_L4_flt_Set_CH
        init-value=2, parameter=KeCPLR_U_UnderCV_L4_flt_Set_OP
        init-value=3, parameter=KeCPLR_dT_ThermalRunaway_flt_Set
        init-value=5, parameter=KeCPLR_t_DeltaCT_L1_flt_Reset
        init-value=5, parameter=KeCPLR_t_DeltaCT_L1_flt_Set
        init-value=5, parameter=KeCPLR_t_DeltaCT_L2_flt_Reset
        init-value=5, parameter=KeCPLR_t_DeltaCT_L2_flt_Set
        init-value=5, parameter=KeCPLR_t_DeltaCT_L3_flt_Reset
        init-value=5, parameter=KeCPLR_t_DeltaCT_L3_flt_Set
        init-value=5, parameter=KeCPLR_t_DeltaCV_L1_flt
        init-value=5, parameter=KeCPLR_t_DeltaCV_L1_flt_Reset
        init-value=5, parameter=KeCPLR_t_DeltaCV_L2_flt
        init-value=5, parameter=KeCPLR_t_DeltaCV_L2_flt_Reset
        init-value=5, parameter=KeCPLR_t_DeltaCV_L3_flt
        init-value=5, parameter=KeCPLR_t_DeltaCV_L3_flt_Reset
        init-value=2, parameter=KeCPLR_t_OverCT_L1_flt_Reset
        init-value=2, parameter=KeCPLR_t_OverCT_L1_flt_Set
        init-value=2, parameter=KeCPLR_t_OverCT_L3_flt_Reset
        init-value=2, parameter=KeCPLR_t_OverCT_L3_flt_Set
        init-value=2, parameter=KeCPLR_t_OverCT_L4_flt_Set
        init-value=1, parameter=KeCPLR_t_OverCV_L1_flt_Reset_OP
        init-value=1, parameter=KeCPLR_t_OverCV_L1_flt_Set
        init-value=1, parameter=KeCPLR_t_OverCV_L3_flt_Reset_OP
        init-value=1, parameter=KeCPLR_t_OverCV_L3_flt_Set
        init-value=1, parameter=KeCPLR_t_OverCV_L4_flt_Set
        init-value=0.5, parameter=KeCPLR_t_PCBOverTemp_flt_Set
        init-value=1, parameter=KeCPLR_t_PackOverVolt_L1_flt_Reset
        init-value=1, parameter=KeCPLR_t_PackOverVolt_L1_flt_Set
        init-value=1, parameter=KeCPLR_t_PackOverVolt_L3_flt_Set
        init-value=1, parameter=KeCPLR_t_PackUnderVolt_L2_flt_Reset
        init-value=1, parameter=KeCPLR_t_PackUnderVolt_L2_flt_Set
        init-value=1, parameter=KeCPLR_t_PackUnderVolt_L3_flt_Reset
        init-value=1, parameter=KeCPLR_t_PackUnderVolt_L3_flt_Set
        init-value=2, parameter=KeCPLR_t_ThermalRunaway_flt_Set
        init-value=2, parameter=KeCPLR_t_ThermalRunaway_flt_TdiffSet
        init-value=2, parameter=KeCPLR_t_ThermalRunaway_flt_TmaxSet
        init-value=0.30000001192092896, parameter=KeCPLR_t_ThermalRunaway_flt_VminSet
        init-value=5, parameter=KeCPLR_t_UnderCT_L1_flt_Reset
        init-value=5, parameter=KeCPLR_t_UnderCT_L1_flt_Set
        init-value=5, parameter=KeCPLR_t_UnderCT_L3_flt_Reset
        init-value=5, parameter=KeCPLR_t_UnderCT_L3_flt_Set
        init-value=5, parameter=KeCPLR_t_UnderCT_L4_flt_Reset
        init-value=5, parameter=KeCPLR_t_UnderCT_L4_flt_Set
        init-value=1, parameter=KeCPLR_t_UnderCV_L2_flt_Reset
        init-value=1, parameter=KeCPLR_t_UnderCV_L2_flt_Set
        init-value=1, parameter=KeCPLR_t_UnderCV_L3_flt_Reset
        init-value=1, parameter=KeCPLR_t_UnderCV_L3_flt_Set
        init-value=1, parameter=KeCPLR_t_UnderCV_L4_flt_Set
        init-value=0, parameter=KeCPLR_b_CellOverVoltRank_En
        init-value=0, parameter=KeCPLR_b_CellUnderVoltRank_En
        init-value=0, parameter=KeCPLR_b_DeltaCT_L{1..3}_flt_En
        init-value=0, parameter=KeCPLR_b_DeltaCT_Rank_CAN_En
        init-value=0, parameter=KeCPLR_b_DeltaCV_L{1..3}_flt_En
        init-value=0, parameter=KeCPLR_b_DeltaCV_Rank_CAN_En
        init-value=0, parameter=KeCPLR_b_DeltaTempRank_En
        init-value=0, parameter=KeCPLR_b_OverCT_L1_flt_En
        init-value=0, parameter=KeCPLR_b_OverCT_L3_flt_En
        init-value=0, parameter=KeCPLR_b_OverCT_L4_flt_En
        init-value=0, parameter=KeCPLR_b_OverCT_Rank_CAN_En
        init-value=0, parameter=KeCPLR_b_OverCV_L1_flt_En
        init-value=0, parameter=KeCPLR_b_OverCV_L3_flt_En
        init-value=0, parameter=KeCPLR_b_OverCV_L4_flt_En
        init-value=0, parameter=KeCPLR_b_OverCV_Rank_CAN_En
        init-value=0, parameter=KeCPLR_b_PCBOverTemp_flt_En
        init-value=0, parameter=KeCPLR_b_PackOverTempRank_En
        init-value=0, parameter=KeCPLR_b_PackOverVoltRank_En
        init-value=0, parameter=KeCPLR_b_PackOverVolt_L1_flt_En
        init-value=0, parameter=KeCPLR_b_PackOverVolt_L3_flt_En
        init-value=0, parameter=KeCPLR_b_PackOverVolt_Rank_CAN_En
        init-value=0, parameter=KeCPLR_b_PackUnderVoltRank_En
        init-value=0, parameter=KeCPLR_b_PackUnderVolt_L2_flt_En
        init-value=0, parameter=KeCPLR_b_PackUnderVolt_L3_flt_En
        init-value=0, parameter=KeCPLR_b_PackUnderVolt_Rank_CAN_En
        init-value=0, parameter=KeCPLR_b_ThermalRunaway_Rank_CAN_En
        init-value=0, parameter=KeCPLR_b_ThermalRunaway_Rank_CAN_Val
        init-value=0, parameter=KeCPLR_b_ThermalRunaway_flt_En
        init-value=0, parameter=KeCPLR_b_UnderCT_L1_flt_En
        init-value=0, parameter=KeCPLR_b_UnderCT_L3_flt_En
        init-value=0, parameter=KeCPLR_b_UnderCT_L4_flt_En
        init-value=0, parameter=KeCPLR_b_UnderCT_Rank_CAN_En
        init-value=0, parameter=KeCPLR_b_UnderCV_L{2..4}_flt_En
        init-value=0, parameter=KeCPLR_b_UnderCV_Rank_CAN_En
        init-value=0, parameter=KeCPLR_k_CellOverVoltRank_Val
        init-value=0, parameter=KeCPLR_k_CellUnderVoltRank_Val
        init-value=0, parameter=KeCPLR_k_DeltaCT_L{1..3}_flt_Val
        init-value=0, parameter=KeCPLR_k_DeltaCT_Rank_CAN_Val
        init-value=0, parameter=KeCPLR_k_DeltaCV_L{1..3}_flt_Val
        init-value=0, parameter=KeCPLR_k_DeltaCV_Rank_CAN_Val
        init-value=0, parameter=KeCPLR_k_DeltaTempRank_Val
        init-value=0, parameter=KeCPLR_k_OverCT_L1_flt_Val
        init-value=0, parameter=KeCPLR_k_OverCT_L3_flt_Val
        init-value=0, parameter=KeCPLR_k_OverCT_L4_flt_Val
        init-value=0, parameter=KeCPLR_k_OverCT_Rank_CAN_Val
        init-value=0, parameter=KeCPLR_k_OverCV_L1_flt_Val
        init-value=0, parameter=KeCPLR_k_OverCV_L3_flt_Val
        init-value=0, parameter=KeCPLR_k_OverCV_L4_flt_Val
        init-value=0, parameter=KeCPLR_k_OverCV_Rank_CAN_Val
        init-value=0, parameter=KeCPLR_k_PCBOverTemp_flt_Val
        init-value=0, parameter=KeCPLR_k_PackOverTempRank_Val
        init-value=0, parameter=KeCPLR_k_PackOverVoltRank_Val
        init-value=0, parameter=KeCPLR_k_PackOverVolt_L1_flt_Val
        init-value=0, parameter=KeCPLR_k_PackOverVolt_L3_flt_Val
        init-value=0, parameter=KeCPLR_k_PackOverVolt_Rank_CAN_Val
        init-value=0, parameter=KeCPLR_k_PackUnderVoltRank_Val
        init-value=0, parameter=KeCPLR_k_PackUnderVolt_L2_flt_Val
        init-value=0, parameter=KeCPLR_k_PackUnderVolt_L3_flt_Val
        init-value=0, parameter=KeCPLR_k_PackUnderVolt_Rank_CAN_Val
        init-value=0, parameter=KeCPLR_k_ThermalRunaway_flt_Val
        init-value=0, parameter=KeCPLR_k_UnderCT_L1_flt_Val
        init-value=0, parameter=KeCPLR_k_UnderCT_L3_flt_Val
        init-value=0, parameter=KeCPLR_k_UnderCT_L4_flt_Val
        init-value=0, parameter=KeCPLR_k_UnderCT_Rank_CAN_Val
        init-value=0, parameter=KeCPLR_k_UnderCV_L{2..4}_flt_Val
        init-value=0, parameter=KeCPLR_k_UnderCV_Rank_CAN_Val
